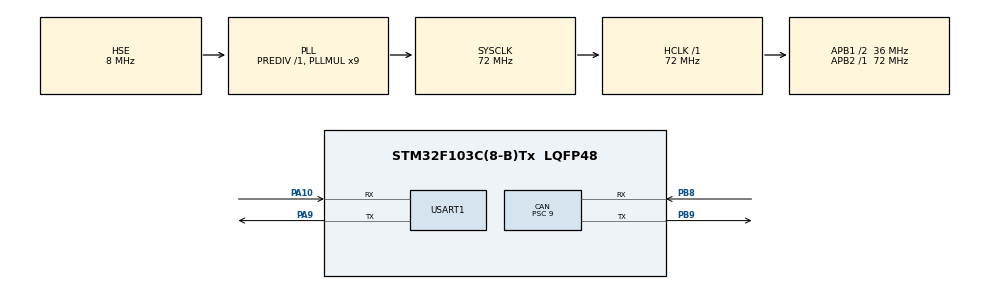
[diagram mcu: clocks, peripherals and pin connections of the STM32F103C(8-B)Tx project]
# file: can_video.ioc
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CAN.BS1=CAN_BS1_13TQ
CAN.BS2=CAN_BS2_2TQ
CAN.CalculateTimeBit=4000
CAN.CalculateTimeQuantum=250.0
CAN.Prescaler=9
Mcu.Family=STM32F1
Mcu.Name=STM32F103C(8-B)Tx
Mcu.Package=LQFP48
NVIC.PriorityGroup=NVIC_PRIORITYGROUP_4
NVIC.USB_LP_CAN1_RX0_IRQn=true\:0\:0\:false\:false\:true\:true\:true
PA10.Mode=Asynchronous
PA10.Signal=USART1_RX
PA9.Mode=Asynchronous
PA9.Signal=USART1_TX
PB8.Mode=Master
PB8.Signal=CAN_RX
PB9.Mode=Master
PB9.Signal=CAN_TX
PD0-OSC_IN.Mode=HSE-External-Oscillator
PD0-OSC_IN.Signal=RCC_OSC_IN
PD1-OSC_OUT.Mode=HSE-External-Oscillator
PD1-OSC_OUT.Signal=RCC_OSC_OUT
ProjectManager.HeapSize=0x200
ProjectManager.StackSize=0x400
ProjectManager.TargetToolchain=TrueSTUDIO
RCC.AHBFreq_Value=72000000
RCC.APB1CLKDivider=RCC_HCLK_DIV2
RCC.APB1Freq_Value=36000000
RCC.APB1TimFreq_Value=72000000
RCC.APB2Freq_Value=72000000
RCC.APB2TimFreq_Value=72000000
RCC.HCLKFreq_Value=72000000
RCC.PLLMUL=RCC_PLL_MUL9
RCC.PLLSourceVirtual=RCC_PLLSOURCE_HSE
RCC.SYSCLKFreq_VALUE=72000000
RCC.SYSCLKSource=RCC_SYSCLKSOURCE_PLLCLK
RCC.USBFreq_Value=72000000
USART1.VirtualMode=VM_ASYNC
VP_SYS_VS_ND.Mode=No_Debug
board=custom

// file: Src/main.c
/* USER CODE BEGIN Header */
/**
  ******************************************************************************
  * @file           : main.c
  * @brief          : Main program body
  ******************************************************************************
  * @attention
  *
  * <h2><center>&copy; Copyright (c) 2019 STMicroelectronics.
  * All rights reserved.</center></h2>
  *
  * This software component is licensed by ST under BSD 3-Clause license,
  * the "License"; You may not use this file except in compliance with the
  * License. You may obtain a copy of the License at:
  *                        opensource.org/licenses/BSD-3-Clause
  *
  ******************************************************************************
  */
/* USER CODE END Header */

#include "main.h"

CAN_HandleTypeDef hcan;
static CAN_TxHeaderTypeDef TxHeader;
static CAN_RxHeaderTypeDef RxHeader;
uint8_t TxData[8];
uint8_t RxData[8];
uint32_t TxMailbox;

UART_HandleTypeDef huart1;

/* USER CODE END PV */

void SystemClock_Config(void);
static void MX_GPIO_Init(void);
static void MX_CAN_Init(void);
static void MX_USART1_UART_Init(void);

int main(void)
{

  /* MCU Configuration--------------------------------------------------------*/

  /* Reset of all peripherals, Initializes the Flash interface and the Systick. */
  HAL_Init();

  /* Configure the system clock */
  SystemClock_Config();

  /* USER CODE BEGIN 2 */

  TxData[0] = 1;
  TxData[1] = 2;
  TxData[2] = 3;
  TxData[3] = 4;
  TxData[4] = 5;
  TxData[5] = 6;
  TxData[6] = 7;
  TxData[7] = 8;

  /* Initialize all configured peripherals */
  MX_GPIO_Init();
  MX_CAN_Init();
  MX_USART1_UART_Init();

  /* Infinite loop */
  /* USER CODE BEGIN WHILE */
  while (1)
  {

      if (HAL_CAN_AddTxMessage(&hcan, &TxHeader, TxData, &TxMailbox) != HAL_OK)
      {
        Error_Handler();
      }
      HAL_Delay(100);

  }
  /* USER CODE END 3 */
}

void SystemClock_Config(void)
{
  RCC_OscInitTypeDef RCC_OscInitStruct = {0};
  RCC_ClkInitTypeDef RCC_ClkInitStruct = {0};

  /** Initializes the CPU, AHB and APB busses clocks
  */
  RCC_OscInitStruct.OscillatorType = RCC_OSCILLATORTYPE_HSE;
  RCC_OscInitStruct.HSEState = RCC_HSE_ON;
  RCC_OscInitStruct.HSEPredivValue = RCC_HSE_PREDIV_DIV1;
  RCC_OscInitStruct.HSIState = RCC_HSI_ON;
  RCC_OscInitStruct.PLL.PLLState = RCC_PLL_ON;
  RCC_OscInitStruct.PLL.PLLSource = RCC_PLLSOURCE_HSE;
  RCC_OscInitStruct.PLL.PLLMUL = RCC_PLL_MUL9;
  if (HAL_RCC_OscConfig(&RCC_OscInitStruct) != HAL_OK)
  {
    Error_Handler();
  }
  /** Initializes the CPU, AHB and APB busses clocks
  */
  RCC_ClkInitStruct.ClockType = RCC_CLOCKTYPE_HCLK|RCC_CLOCKTYPE_SYSCLK
                              |RCC_CLOCKTYPE_PCLK1|RCC_CLOCKTYPE_PCLK2;
  RCC_ClkInitStruct.SYSCLKSource = RCC_SYSCLKSOURCE_PLLCLK;
  RCC_ClkInitStruct.AHBCLKDivider = RCC_SYSCLK_DIV1;
  RCC_ClkInitStruct.APB1CLKDivider = RCC_HCLK_DIV2;
  RCC_ClkInitStruct.APB2CLKDivider = RCC_HCLK_DIV1;

  if (HAL_RCC_ClockConfig(&RCC_ClkInitStruct, FLASH_LATENCY_2) != HAL_OK)
  {
    Error_Handler();
  }

}

static void MX_CAN_Init(void)
{

  hcan.Instance = CAN1;
  hcan.Init.Prescaler = 9;
  hcan.Init.Mode = CAN_MODE_NORMAL;
  hcan.Init.SyncJumpWidth = CAN_SJW_1TQ;
  hcan.Init.TimeSeg1 = CAN_BS1_13TQ;
  hcan.Init.TimeSeg2 = CAN_BS2_2TQ;
  hcan.Init.TimeTriggeredMode = DISABLE;
  hcan.Init.AutoBusOff = DISABLE;
  hcan.Init.AutoWakeUp = DISABLE;
  hcan.Init.AutoRetransmission = DISABLE;
  hcan.Init.ReceiveFifoLocked = DISABLE;
  hcan.Init.TransmitFifoPriority = DISABLE;
  if (HAL_CAN_Init(&hcan) != HAL_OK)
  {
    Error_Handler();
  }

  CAN_FilterTypeDef  sFilterConfig;

    /* Configure the CAN Filter */
  sFilterConfig.FilterBank = 0;
  sFilterConfig.FilterMode = CAN_FILTERMODE_IDMASK;
  sFilterConfig.FilterScale = CAN_FILTERSCALE_32BIT;
  sFilterConfig.FilterIdHigh = 0x0000;
  sFilterConfig.FilterIdLow = 0x0000;
  sFilterConfig.FilterMaskIdHigh = 0x0000;
  sFilterConfig.FilterMaskIdLow = 0x0000;
  sFilterConfig.FilterFIFOAssignment = CAN_RX_FIFO0;
  sFilterConfig.FilterActivation = ENABLE;
  sFilterConfig.SlaveStartFilterBank = 14;

  if (HAL_CAN_ConfigFilter(&hcan, &sFilterConfig) != HAL_OK)
  {
    /* Filter configuration Error */
    Error_Handler();
  }

  /* Start the CAN peripheral */
  if (HAL_CAN_Start(&hcan) != HAL_OK)
  {
    /* Start Error */
    Error_Handler();
  }

  if (HAL_CAN_ActivateNotification(&hcan, CAN_IT_RX_FIFO0_MSG_PENDING | CAN_IT_TX_MAILBOX_EMPTY) != HAL_OK)
  {
  /* Notification Error */
  Error_Handler();
  }

  /* Configure Transmission process */
  TxHeader.StdId = 0x010;
  TxHeader.ExtId = 0x01;
  TxHeader.RTR = CAN_RTR_DATA;
  TxHeader.IDE = CAN_ID_STD;
  TxHeader.DLC = 8;
  TxHeader.TransmitGlobalTime = DISABLE;

}

static void MX_USART1_UART_Init(void)
{

  huart1.Instance = USART1;
  huart1.Init.BaudRate = 115200;
  huart1.Init.WordLength = UART_WORDLENGTH_8B;
  huart1.Init.StopBits = UART_STOPBITS_1;
  huart1.Init.Parity = UART_PARITY_NONE;
  huart1.Init.Mode = UART_MODE_TX_RX;
  huart1.Init.HwFlowCtl = UART_HWCONTROL_NONE;
  huart1.Init.OverSampling = UART_OVERSAMPLING_16;
  if (HAL_UART_Init(&huart1) != HAL_OK)
  {
    Error_Handler();
  }

}

static void MX_GPIO_Init(void)
{
  GPIO_InitTypeDef GPIO_InitStruct = {0};

  /* GPIO Ports Clock Enable */
  __HAL_RCC_GPIOC_CLK_ENABLE();
  __HAL_RCC_GPIOD_CLK_ENABLE();
  __HAL_RCC_GPIOA_CLK_ENABLE();

  /*Configure GPIO pin Output Level */
  HAL_GPIO_WritePin(GPIOC, GPIO_PIN_13, GPIO_PIN_SET);

  /*Configure GPIO pin : PC13 */
  GPIO_InitStruct.Pin = GPIO_PIN_13;
  GPIO_InitStruct.Mode = GPIO_MODE_OUTPUT_PP;
  GPIO_InitStruct.Pull = GPIO_NOPULL;
  GPIO_InitStruct.Speed = GPIO_SPEED_FREQ_LOW;
  HAL_GPIO_Init(GPIOC, &GPIO_InitStruct);

}

/* USER CODE BEGIN 4 */
void HAL_CAN_RxFifo0MsgPendingCallback(CAN_HandleTypeDef *hcan)
{
  /* Get RX message */
  if (HAL_CAN_GetRxMessage(hcan, CAN_RX_FIFO0, &RxHeader, RxData) != HAL_OK)
  {
    /* Reception Error */
    Error_Handler();
  }
}

/* USER CODE END 4 */

void Error_Handler(void)
{
  /* USER CODE BEGIN Error_Handler_Debug */
  /* User can add his own implementation to report the HAL error return state */
	HAL_GPIO_TogglePin(GPIOC,GPIO_PIN_13);
	HAL_Delay(100);
  /* USER CODE END Error_Handler_Debug */
}

/************************ (C) COPYRIGHT STMicroelectronics *****END OF FILE****/
